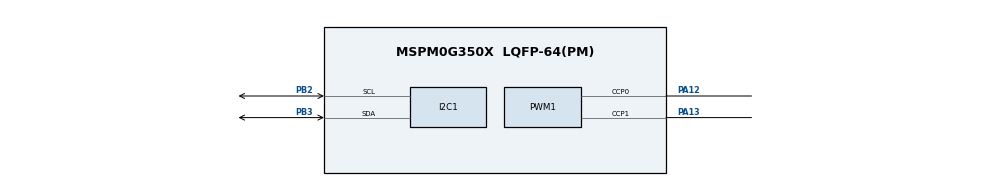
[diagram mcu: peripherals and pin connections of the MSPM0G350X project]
/**
 * @cliArgs --device "MSPM0G350X" --part "Default" --package "LQFP-64(PM)" --product "mspm0_sdk@2.10.00.04"
 * @versions {"tool":"1.27.0+4565"}
 */

/**
 * Import the modules used in this configuration.
 */
const GPIO   = scripting.addModule("/ti/driverlib/GPIO", {}, false);
const GPIO1  = GPIO.addInstance();
const GPIO2  = GPIO.addInstance();
const GPIO3  = GPIO.addInstance();
const GPIO4  = GPIO.addInstance();
const I2C    = scripting.addModule("/ti/driverlib/I2C", {}, false);
const I2C1   = I2C.addInstance();
const PWM    = scripting.addModule("/ti/driverlib/PWM", {}, false);
const PWM1   = PWM.addInstance();
const SYSCTL = scripting.addModule("/ti/driverlib/SYSCTL");
const TIMER  = scripting.addModule("/ti/driverlib/TIMER", {}, false);
const TIMER1 = TIMER.addInstance();

/**
 * Write custom configuration values to the imported modules.
 */
GPIO1.$name                          = "MOTOR";
GPIO1.associatedPins.create(5);
GPIO1.associatedPins[0].assignedPort = "PORTA";
GPIO1.associatedPins[0].$name        = "A_IN1";
GPIO1.associatedPins[0].assignedPin  = "24";
GPIO1.associatedPins[1].assignedPort = "PORTA";
GPIO1.associatedPins[1].$name        = "A_IN2";
GPIO1.associatedPins[1].assignedPin  = "25";
GPIO1.associatedPins[2].assignedPort = "PORTB";
GPIO1.associatedPins[2].assignedPin  = "9";
GPIO1.associatedPins[2].$name        = "B_IN1";
GPIO1.associatedPins[3].assignedPort = "PORTB";
GPIO1.associatedPins[3].assignedPin  = "8";
GPIO1.associatedPins[3].$name        = "B_IN2";
GPIO1.associatedPins[4].assignedPort = "PORTB";
GPIO1.associatedPins[4].assignedPin  = "22";
GPIO1.associatedPins[4].initialValue = "SET";
GPIO1.associatedPins[4].$name        = "STBY";

const Board = scripting.addModule("/ti/driverlib/Board", {}, false);

GPIO2.$name                              = "KEY";
GPIO2.associatedPins[0].$name            = "SET";
GPIO2.associatedPins[0].direction        = "INPUT";
GPIO2.associatedPins[0].internalResistor = "PULL_UP";
GPIO2.associatedPins[0].assignedPort     = "PORTB";
GPIO2.associatedPins[0].assignedPin      = "21";

GPIO3.$name                              = "ENCODER";
GPIO3.associatedPins.create(4);
GPIO3.associatedPins[0].$name            = "ENC_LA";
GPIO3.associatedPins[0].direction        = "INPUT";
GPIO3.associatedPins[0].assignedPort     = "PORTA";
GPIO3.associatedPins[0].assignedPin      = "14";
GPIO3.associatedPins[0].internalResistor = "PULL_UP";
GPIO3.associatedPins[1].direction        = "INPUT";
GPIO3.associatedPins[1].$name            = "ENC_LB";
GPIO3.associatedPins[1].assignedPort     = "PORTA";
GPIO3.associatedPins[1].assignedPin      = "15";
GPIO3.associatedPins[1].internalResistor = "PULL_UP";
GPIO3.associatedPins[2].direction        = "INPUT";
GPIO3.associatedPins[2].$name            = "ENC_RA";
GPIO3.associatedPins[2].assignedPort     = "PORTB";
GPIO3.associatedPins[2].assignedPin      = "12";
GPIO3.associatedPins[2].internalResistor = "PULL_UP";
GPIO3.associatedPins[3].direction        = "INPUT";
GPIO3.associatedPins[3].$name            = "ENC_RB";
GPIO3.associatedPins[3].assignedPort     = "PORTB";
GPIO3.associatedPins[3].assignedPin      = "13";
GPIO3.associatedPins[3].internalResistor = "PULL_UP";

GPIO4.$name                          = "DISPLAY";
GPIO4.associatedPins.create(6);
GPIO4.associatedPins[0].$name        = "LCD_SDA";
GPIO4.associatedPins[0].assignedPort = "PORTB";
GPIO4.associatedPins[0].assignedPin  = "0";
GPIO4.associatedPins[0].initialValue = "SET";
GPIO4.associatedPins[1].$name        = "LCD_SCL";
GPIO4.associatedPins[1].assignedPort = "PORTB";
GPIO4.associatedPins[1].assignedPin  = "1";
GPIO4.associatedPins[1].initialValue = "SET";
GPIO4.associatedPins[2].$name        = "LCD_CS";
GPIO4.associatedPins[2].assignedPort = "PORTB";
GPIO4.associatedPins[2].assignedPin  = "4";
GPIO4.associatedPins[2].initialValue = "SET";
GPIO4.associatedPins[3].$name        = "LCD_DC";
GPIO4.associatedPins[3].assignedPort = "PORTB";
GPIO4.associatedPins[3].assignedPin  = "5";
GPIO4.associatedPins[3].initialValue = "SET";
GPIO4.associatedPins[4].$name        = "LCD_BLK";
GPIO4.associatedPins[4].assignedPort = "PORTA";
GPIO4.associatedPins[4].assignedPin  = "17";
GPIO4.associatedPins[4].initialValue = "SET";
GPIO4.associatedPins[5].$name        = "LCD_RST";
GPIO4.associatedPins[5].assignedPort = "PORTA";
GPIO4.associatedPins[5].assignedPin  = "18";
GPIO4.associatedPins[5].initialValue = "SET";

I2C1.basicEnableController             = true;
I2C1.$name                             = "I2C_BUS";
I2C1.peripheral.sdaPin.$assign         = "PB3";
I2C1.peripheral.sclPin.$assign         = "PB2";
I2C1.sdaPinConfig.hideOutputInversion  = scripting.forceWrite(false);
I2C1.sdaPinConfig.onlyInternalResistor = scripting.forceWrite(false);
I2C1.sdaPinConfig.passedPeripheralType = scripting.forceWrite("Digital");
I2C1.sdaPinConfig.$name                = "ti_driverlib_gpio_GPIOPinGeneric2";
I2C1.sdaPinConfig.internalResistor     = "PULL_UP";
I2C1.sdaPinConfig.enableConfig         = true;
I2C1.sclPinConfig.hideOutputInversion  = scripting.forceWrite(false);
I2C1.sclPinConfig.onlyInternalResistor = scripting.forceWrite(false);
I2C1.sclPinConfig.passedPeripheralType = scripting.forceWrite("Digital");
I2C1.sclPinConfig.$name                = "ti_driverlib_gpio_GPIOPinGeneric3";
I2C1.sclPinConfig.enableConfig         = true;
I2C1.sclPinConfig.internalResistor     = "PULL_UP";

PWM1.$name                      = "PWM_0";
PWM1.pwmMode                    = "EDGE_ALIGN_UP";
PWM1.timerStartTimer            = true;
PWM1.peripheral.ccp0Pin.$assign = "PA12";
PWM1.peripheral.ccp1Pin.$assign = "PA13";
PWM1.PWM_CHANNEL_0.$name        = "ti_driverlib_pwm_PWMTimerCC0";
PWM1.PWM_CHANNEL_1.$name        = "ti_driverlib_pwm_PWMTimerCC1";
PWM1.ccp0PinConfig.$name        = "ti_driverlib_gpio_GPIOPinGeneric0";
PWM1.ccp1PinConfig.$name        = "ti_driverlib_gpio_GPIOPinGeneric1";

TIMER1.$name              = "CTRL_TIMER";
TIMER1.timerPeriod        = "1 ms";
TIMER1.timerMode          = "PERIODIC";
TIMER1.interrupts         = ["ZERO"];
TIMER1.peripheral.$assign = "TIMG12";

SYSCTL.forceDefaultClkConfig = true;

/**
 * Pinmux solution for unlocked pins/peripherals. This ensures that minor changes to the automatic solver in a future
 * version of the tool will not impact the pinmux you originally saw.  These lines can be completely deleted in order to
 * re-solve from scratch.
 */
GPIO1.associatedPins[0].pin.$suggestSolution = "PA24";
GPIO1.associatedPins[1].pin.$suggestSolution = "PA25";
GPIO1.associatedPins[2].pin.$suggestSolution = "PB9";
GPIO1.associatedPins[3].pin.$suggestSolution = "PB8";
GPIO1.associatedPins[4].pin.$suggestSolution = "PB22";
Board.peripheral.$suggestSolution            = "DEBUGSS";
Board.peripheral.swclkPin.$suggestSolution   = "PA20";
Board.peripheral.swdioPin.$suggestSolution   = "PA19";
GPIO2.associatedPins[0].pin.$suggestSolution = "PB21";
GPIO3.associatedPins[0].pin.$suggestSolution = "PA14";
GPIO3.associatedPins[1].pin.$suggestSolution = "PA15";
GPIO3.associatedPins[2].pin.$suggestSolution = "PB12";
GPIO3.associatedPins[3].pin.$suggestSolution = "PB13";
GPIO4.associatedPins[0].pin.$suggestSolution = "PB0";
GPIO4.associatedPins[1].pin.$suggestSolution = "PB1";
GPIO4.associatedPins[2].pin.$suggestSolution = "PB4";
GPIO4.associatedPins[3].pin.$suggestSolution = "PB5";
GPIO4.associatedPins[4].pin.$suggestSolution = "PA17";
GPIO4.associatedPins[5].pin.$suggestSolution = "PA18";
I2C1.peripheral.$suggestSolution             = "I2C1";
PWM1.peripheral.$suggestSolution             = "TIMG0";
SYSCTL.peripheral.$suggestSolution           = "SYSCTL";
